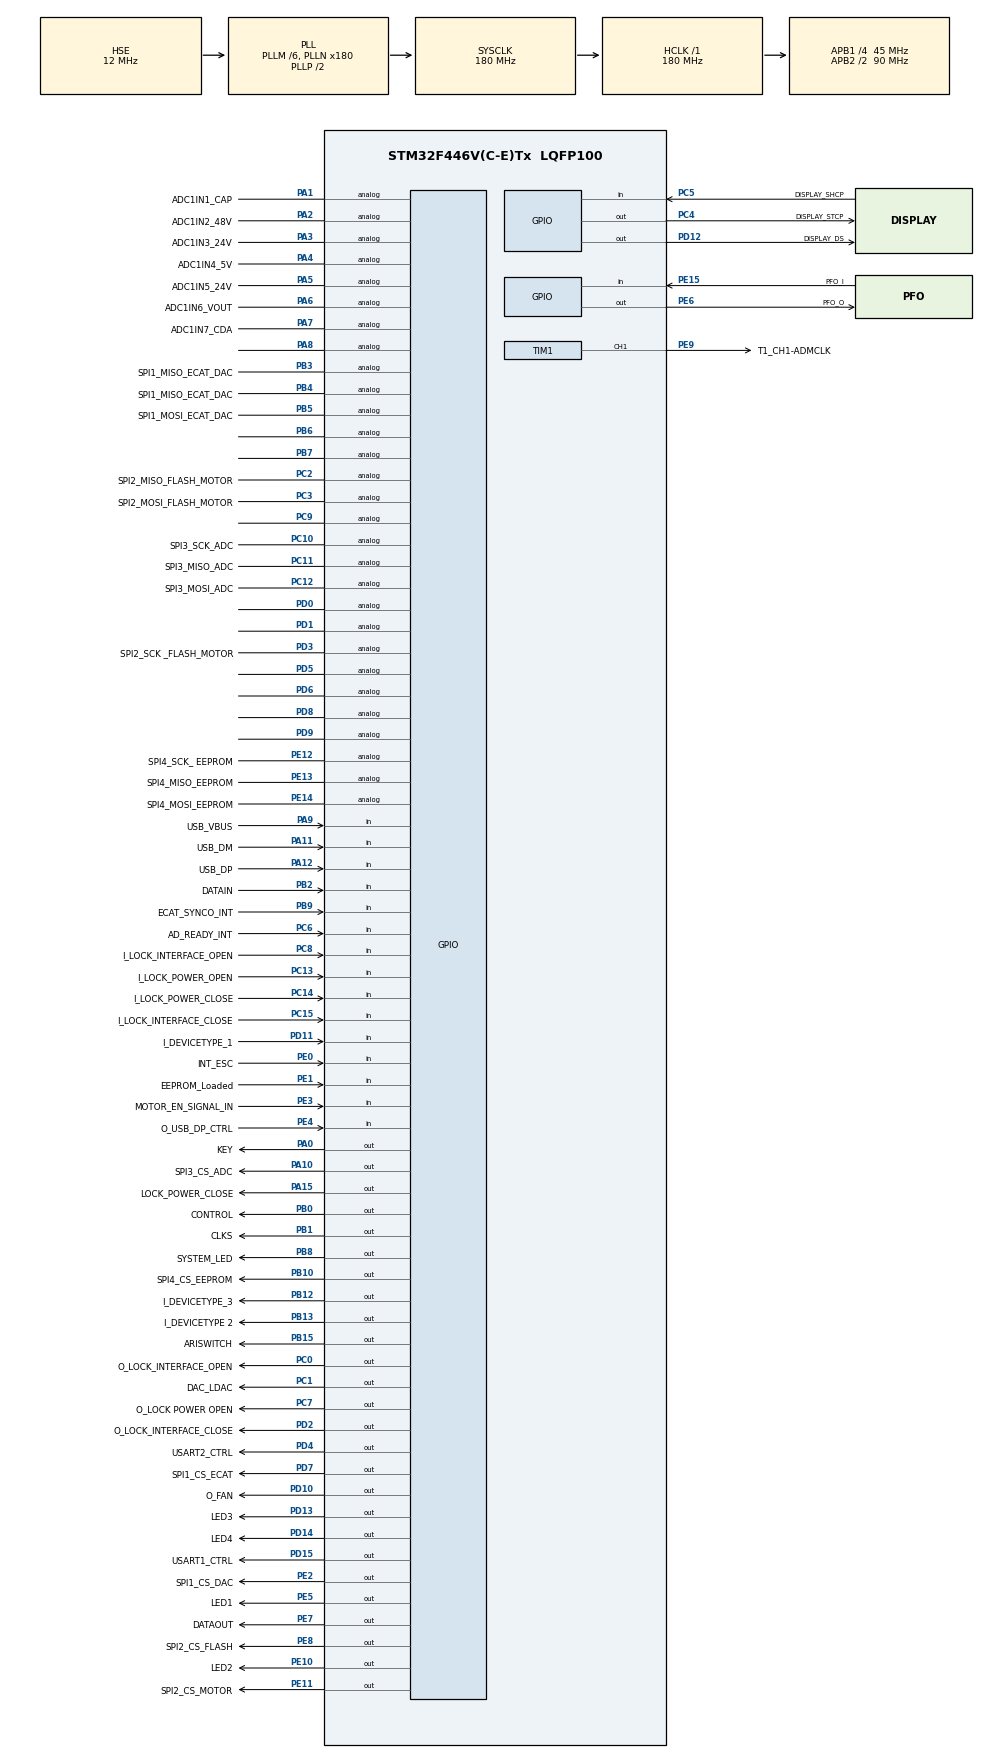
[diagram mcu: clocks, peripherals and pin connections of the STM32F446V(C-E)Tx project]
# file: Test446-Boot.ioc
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board=custom
Dma.ADC1.0.Direction=DMA_PERIPH_TO_MEMORY
Dma.ADC1.0.FIFOMode=DMA_FIFOMODE_DISABLE
Dma.ADC1.0.Instance=DMA2_Stream0
Dma.ADC1.0.MemDataAlignment=DMA_MDATAALIGN_WORD
Dma.ADC1.0.MemInc=DMA_MINC_ENABLE
Dma.ADC1.0.Mode=DMA_CIRCULAR
Dma.ADC1.0.PeriphDataAlignment=DMA_PDATAALIGN_WORD
Dma.ADC1.0.PeriphInc=DMA_PINC_DISABLE
Dma.ADC1.0.Priority=DMA_PRIORITY_LOW
Dma.I2C3_RX.1.Direction=DMA_PERIPH_TO_MEMORY
Dma.I2C3_RX.1.FIFOMode=DMA_FIFOMODE_DISABLE
Dma.I2C3_RX.1.Instance=DMA1_Stream1
Dma.I2C3_RX.1.MemDataAlignment=DMA_MDATAALIGN_BYTE
Dma.I2C3_RX.1.MemInc=DMA_MINC_ENABLE
Dma.I2C3_RX.1.Mode=DMA_NORMAL
Dma.I2C3_RX.1.PeriphDataAlignment=DMA_PDATAALIGN_BYTE
Dma.I2C3_RX.1.PeriphInc=DMA_PINC_DISABLE
Dma.I2C3_RX.1.Priority=DMA_PRIORITY_LOW
Dma.I2C3_TX.2.Direction=DMA_MEMORY_TO_PERIPH
Dma.I2C3_TX.2.FIFOMode=DMA_FIFOMODE_DISABLE
Dma.I2C3_TX.2.Instance=DMA1_Stream4
Dma.I2C3_TX.2.MemDataAlignment=DMA_MDATAALIGN_BYTE
Dma.I2C3_TX.2.MemInc=DMA_MINC_ENABLE
Dma.I2C3_TX.2.Mode=DMA_NORMAL
Dma.I2C3_TX.2.PeriphDataAlignment=DMA_PDATAALIGN_BYTE
Dma.I2C3_TX.2.PeriphInc=DMA_PINC_DISABLE
Dma.I2C3_TX.2.Priority=DMA_PRIORITY_LOW
Dma.Request0=ADC1
Dma.Request1=I2C3_RX
Dma.Request2=I2C3_TX
IWDG.Prescaler=IWDG_PRESCALER_32
Mcu.Family=STM32F4
Mcu.Name=STM32F446V(C-E)Tx
Mcu.Package=LQFP100
NVIC.OTG_FS_IRQn=true\:5\:0\:false\:false\:true\:true\:true\:true\:true
NVIC.PriorityGroup=NVIC_PRIORITYGROUP_4
NVIC.TIM7_IRQn=true\:15\:0\:false\:false\:true\:false\:false\:true\:true
NVIC.TimeBase=TIM7_IRQn
NVIC.TimeBaseIP=TIM7
PA0-WKUP.GPIO_Label=KEY
PA0-WKUP.Signal=GPIO_Output
PA1.GPIO_Label=ADC1IN1_CAP
PA1.Signal=GPIO_Analog
PA10.GPIO_Label=SPI3_CS_ADC
PA10.Signal=GPIO_Output
PA11.GPIO_Label=USB_DM
PA11.GPIO_PuPd=GPIO_NOPULL
PA11.Signal=GPIO_Input
PA12.GPIO_Label=USB_DP
PA12.GPIO_PuPd=GPIO_NOPULL
PA12.Signal=GPIO_Input
PA13.Mode=Serial_Wire
PA13.Signal=SYS_JTMS-SWDIO
PA14.Mode=Serial_Wire
PA14.Signal=SYS_JTCK-SWCLK
PA15.GPIO_Label=LOCK_POWER_CLOSE
PA15.Signal=GPIO_Output
PA2.GPIO_Label=ADC1IN2_48V
PA2.Signal=GPIO_Analog
PA3.GPIO_Label=ADC1IN3_24V
PA3.Signal=GPIO_Analog
PA4.GPIO_Label=ADC1IN4_5V
PA4.Signal=GPIO_Analog
PA5.GPIO_Label=ADC1IN5_24V
PA5.Signal=GPIO_Analog
PA6.GPIO_Label=ADC1IN6_VOUT
PA6.Signal=GPIO_Analog
PA7.GPIO_Label=ADC1IN7_CDA
PA7.Signal=GPIO_Analog
PA8.GPIO_Pu=GPIO_PULLUP
PA8.Signal=GPIO_Analog
PA9.GPIO_Label=USB_VBUS
PA9.GPIO_PuPd=GPIO_NOPULL
PA9.Signal=GPIO_Input
PB0.GPIO_Label=CONTROL
PB0.Signal=GPIO_Output
PB1.GPIO_Label=CLKS
PB1.Signal=GPIO_Output
PB10.GPIO_Label=SPI4_CS_EEPROM
PB10.Signal=GPIO_Output
PB12.GPIO_Label=I_DEVICETYPE_3
PB12.Signal=GPIO_Output
PB13.GPIO_Label=I_DEVICETYPE 2
PB13.Signal=GPIO_Output
PB15.GPIO_Label=ARISWITCH
PB15.Signal=GPIO_Output
PB2.GPIO_Label=DATAIN
PB2.Signal=GPIO_Input
PB3.GPIO_Label=SPI1_MISO_ECAT_DAC
PB3.GPIO_PuPd=GPIO_PULLUP
PB3.Signal=GPIO_Analog
PB4.GPIO_Label=SPI1_MISO_ECAT_DAC
PB4.GPIO_PuPd=GPIO_PULLUP
PB4.Signal=GPIO_Analog
PB5.GPIO_Label=SPI1_MOSI_ECAT_DAC
PB5.GPIO_PuPd=GPIO_PULLUP
PB5.Signal=GPIO_Analog
PB6.Signal=GPIO_Analog
PB7.Signal=GPIO_Analog
PB8.GPIO_Label=SYSTEM_LED
PB8.Signal=GPIO_Output
PB9.GPIO_Label=ECAT_SYNCO_INT
PB9.Signal=GPIO_Input
PC0.GPIO_Label=O_LOCK_INTERFACE_OPEN
PC0.Signal=GPIO_Output
PC1.GPIO_Label=DAC_LDAC
PC1.Signal=GPIO_Output
PC10.GPIO_Label=SPI3_SCK_ADC
PC10.GPIO_PuPd=GPIO_PULLUP
PC10.Signal=GPIO_Analog
PC11.GPIO_Label=SPI3_MISO_ADC
PC11.GPIO_PuPd=GPIO_PULLUP
PC11.Signal=GPIO_Analog
PC12.GPIO_Label=SPI3_MOSI_ADC
PC12.GPIO_PuPd=GPIO_PULLUP
PC12.Signal=GPIO_Analog
PC13.GPIO_Label=I_LOCK_POWER_OPEN
PC13.Signal=GPIO_Input
PC14-OSC32_IN.GPIO_Label=I_LOCK_POWER_CLOSE
PC14-OSC32_IN.Signal=GPIO_Input
PC15-OSC32_OUT.GPIO_Label=I_LOCK_INTERFACE_CLOSE
PC15-OSC32_OUT.Signal=GPIO_Input
PC2.GPIO_Label=SPI2_MISO_FLASH_MOTOR
PC2.GPIO_PuPd=GPIO_PULLUP
PC2.Signal=GPIO_Analog
PC3.GPIO_Label=SPI2_MOSI_FLASH_MOTOR
PC3.GPIO_PuPd=GPIO_PULLUP
PC3.Signal=GPIO_Analog
PC4.GPIO_Label=DISPLAY_STCP
PC4.Signal=GPIO_Output
PC5.GPIO_Label=DISPLAY_SHCP
PC5.Signal=GPIO_Input
PC6.GPIO_Label=AD_READY_INT
PC6.Signal=GPIO_Input
PC7.GPIO_Label=O_LOCK POWER OPEN
PC7.Signal=GPIO_Output
PC8.GPIO_Label=I_LOCK_INTERFACE_OPEN
PC8.Signal=GPIO_Input
PC9.GPIO_Pu=GPIO_PULLUP
PC9.Signal=GPIO_Analog
PD0.GPIO_PuPd=GPIO_NOPULL
PD0.Signal=GPIO_Analog
PD1.GPIO_PuPd=GPIO_NOPULL
PD1.Signal=GPIO_Analog
PD10.GPIO_Label=O_FAN
PD10.Signal=GPIO_Output
PD11.GPIO_Label=I_DEVICETYPE_1
PD11.Signal=GPIO_Input
PD12.GPIO_Label=DISPLAY_DS
PD12.Signal=GPIO_Output
PD13.GPIO_Label=LED3
PD13.Signal=GPIO_Output
PD14.GPIO_Label=LED4
PD14.Signal=GPIO_Output
PD15.GPIO_Label=USART1_CTRL
PD15.Signal=GPIO_Output
PD2.GPIO_Label=O_LOCK_INTERFACE_CLOSE
PD2.GPIO_PuPd=GPIO_PULLUP
PD2.Signal=GPIO_Output
PD3.GPIO_Label=SPI2_SCK _FLASH_MOTOR
PD3.GPIO_PuPd=GPIO_PULLUP
PD3.Signal=GPIO_Analog
PD4.GPIO_Label=USART2_CTRL
PD4.Signal=GPIO_Output
PD5.Signal=GPIO_Analog
PD6.Signal=GPIO_Analog
PD7.GPIO_Label=SPI1_CS_ECAT
PD7.Signal=GPIO_Output
PD8.Signal=GPIO_Analog
PD9.Signal=GPIO_Analog
PE0.GPIO_Label=INT_ESC
PE0.Signal=GPIO_Input
PE1.GPIO_Label=EEPROM_Loaded
PE1.Signal=GPIO_Input
PE10.GPIO_Label=LED2
PE10.Signal=GPIO_Output
PE11.GPIO_Label=SPI2_CS_MOTOR
PE11.PinState=GPIO_PIN_SET
PE11.Signal=GPIO_Output
PE12.GPIO_Label=SPI4_SCK_ EEPROM
PE12.GPIO_PuPd=GPIO_PULLUP
PE12.Signal=GPIO_Analog
PE13.GPIO_Label=SPI4_MISO_EEPROM
PE13.GPIO_PuPd=GPIO_PULLUP
PE13.Signal=GPIO_Analog
PE14.GPIO_Label=SPI4_MOSI_EEPROM
PE14.GPIO_PuPd=GPIO_PULLUP
PE14.Signal=GPIO_Analog
PE15.GPIO_Label=PFO_I
PE15.Signal=GPIO_Input
PE2.GPIO_Label=SPI1_CS_DAC
PE2.Signal=GPIO_Output
PE3.GPIO_Label=MOTOR_EN_SIGNAL_IN
PE3.Signal=GPIO_Input
PE4.GPIO_Label=O_USB_DP_CTRL
PE4.GPIO_PuPd=GPIO_NOPULL
PE4.Signal=GPIO_Input
PE5.GPIO_Label=LED1
PE5.Signal=GPIO_Output
PE6.GPIO_Label=PFO_O
PE6.Signal=GPIO_Output
PE7.GPIO_Label=DATAOUT
PE7.Signal=GPIO_Output
PE8.GPIO_Label=SPI2_CS_FLASH
PE8.PinState=GPIO_PIN_SET
PE8.Signal=GPIO_Output
PE9.GPIO_Label=T1_CH1-ADMCLK
PE9.GPIO_PuPd=GPIO_PULLUP
PE9.GPIO_Speed=GPIO_SPEED_FREQ_VERY_HIGH
PE9.Signal=S_TIM1_CH1
PH0-OSC_IN.Mode=HSE-External-Clock-Source
PH0-OSC_IN.Signal=RCC_OSC_IN
PH1-OSC_OUT.Mode=HSE-External-Clock-Source
PH1-OSC_OUT.Signal=RCC_OSC_OUT
ProjectManager.HeapSize=0x200
ProjectManager.StackSize=0x500
ProjectManager.TargetToolchain=STM32CubeIDE
RCC.AHBFreq_Value=180000000
RCC.APB1CLKDivider=RCC_HCLK_DIV4
RCC.APB1Freq_Value=45000000
RCC.APB1TimFreq_Value=90000000
RCC.APB2CLKDivider=RCC_HCLK_DIV2
RCC.APB2Freq_Value=90000000
RCC.APB2TimFreq_Value=180000000
RCC.CortexFreq_Value=180000000
RCC.HCLKFreq_Value=180000000
RCC.HSE_VALUE=12000000
RCC.PLLM=6
RCC.PLLN=180
RCC.PLLQ=3
RCC.PLLSAIM=6
RCC.PLLSAIN=96
RCC.PLLSAIP=RCC_PLLSAIP_DIV4
RCC.PWR_Regulator_Voltage_Scale=PWR_REGULATOR_VOLTAGE_SCALE1
RCC.PWREXT_OverDrive=PWREXT_OverDrive_ACTIVATED
RCC.SYSCLKFreq_VALUE=180000000
RCC.SYSCLKSource=RCC_SYSCLKSOURCE_PLLCLK
RCC.USBCLockSelection=RCC_CLK48CLKSOURCE_PLLSAIP
RCC.USBFreq_Value=48000000
RCC.VCOOutputFreq_Value=360000000
SH.ADCx_IN1.0=ADC1_IN1,IN1
SH.ADCx_IN2.0=ADC1_IN2,IN2
SH.ADCx_IN3.0=ADC1_IN3,IN3
SH.ADCx_IN4.0=ADC1_IN4,IN4
SH.ADCx_IN5.0=ADC1_IN5,IN5
SH.ADCx_IN6.0=ADC1_IN6,IN6
SH.ADCx_IN7.0=ADC1_IN7,IN7
SH.S_TIM1_CH1.0=TIM1_CH1,PWM Generation1 CH1
VP_IWDG_VS_IWDG.Mode=IWDG_Activate
VP_SYS_VS_tim7.Mode=TIM7
VP_TIM1_VS_ClockSourceINT.Mode=Internal
VP_TIM10_VS_ClockSourceINT.Mode=Enable_Timer
VP_TIM11_VS_ClockSourceINT.Mode=Enable_Timer
VP_TIM12_VS_ClockSourceINT.Mode=Internal
VP_TIM3_VS_ClockSourceINT.Mode=Internal
VP_TIM9_VS_ClockSourceINT.Mode=Internal
RCC.PLLSourceVirtual=RCC_PLLSOURCE_HSE

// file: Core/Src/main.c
/* 独立裸机 Boot；GPIO 安全初态和时钟沿用目标 12MHz 工程。 */
#include "main.h"
/* USER CODE BEGIN Includes */
#include "board.h"
#include "usb_io.h"
#include "usb_proto.h"
#include "fw_platform.h"
/* USER CODE END Includes */
IWDG_HandleTypeDef hiwdg;
void SystemClock_Config(void);
static void MX_GPIO_Init(void);
static void MX_IWDG_Init(void);
int main(void)
{
  HAL_Init(); SystemClock_Config(); MX_GPIO_Init(); MX_IWDG_Init();
  /* USER CODE BEGIN 2 */
  usb_io_init(); fw_platform_boot_start();
  if (!usb_io_stack_init()) Error_Handler();
  /* USER CODE END 2 */
  while (1) {
    /* USER CODE BEGIN 3 */
    usb_io_task(); usb_proto_task(); fw_platform_task(); board_watchdog_refresh();
  }
  /* USER CODE END 3 */
}
void SystemClock_Config(void)
{
  RCC_OscInitTypeDef RCC_OscInitStruct = {0};
  RCC_ClkInitTypeDef RCC_ClkInitStruct = {0};

  /** Configure the main internal regulator output voltage
  */
  __HAL_RCC_PWR_CLK_ENABLE();
  __HAL_PWR_VOLTAGESCALING_CONFIG(PWR_REGULATOR_VOLTAGE_SCALE1);

  /** Initializes the RCC Oscillators according to the specified parameters
  * in the RCC_OscInitTypeDef structure.
  */
  RCC_OscInitStruct.OscillatorType = RCC_OSCILLATORTYPE_LSI|RCC_OSCILLATORTYPE_HSE;
  RCC_OscInitStruct.HSEState = RCC_HSE_BYPASS;
  RCC_OscInitStruct.LSIState = RCC_LSI_ON;
  RCC_OscInitStruct.PLL.PLLState = RCC_PLL_ON;
  RCC_OscInitStruct.PLL.PLLSource = RCC_PLLSOURCE_HSE;
  RCC_OscInitStruct.PLL.PLLM = 6;
  RCC_OscInitStruct.PLL.PLLN = 180;
  RCC_OscInitStruct.PLL.PLLP = RCC_PLLP_DIV2;
  RCC_OscInitStruct.PLL.PLLQ = 3;
  RCC_OscInitStruct.PLL.PLLR = 2;
  if (HAL_RCC_OscConfig(&RCC_OscInitStruct) != HAL_OK)
  {
    Error_Handler();
  }

  /** Activate the Over-Drive mode
  */
  if (HAL_PWREx_EnableOverDrive() != HAL_OK)
  {
    Error_Handler();
  }

  /** Initializes the CPU, AHB and APB buses clocks
  */
  RCC_ClkInitStruct.ClockType = RCC_CLOCKTYPE_HCLK|RCC_CLOCKTYPE_SYSCLK
                              |RCC_CLOCKTYPE_PCLK1|RCC_CLOCKTYPE_PCLK2;
  RCC_ClkInitStruct.SYSCLKSource = RCC_SYSCLKSOURCE_PLLCLK;
  RCC_ClkInitStruct.AHBCLKDivider = RCC_SYSCLK_DIV1;
  RCC_ClkInitStruct.APB1CLKDivider = RCC_HCLK_DIV4;
  RCC_ClkInitStruct.APB2CLKDivider = RCC_HCLK_DIV2;

  if (HAL_RCC_ClockConfig(&RCC_ClkInitStruct, FLASH_LATENCY_5) != HAL_OK)
  {
    Error_Handler();
  }
}
static void MX_GPIO_Init(void)
{
  GPIO_InitTypeDef GPIO_InitStruct = {0};

  /* GPIO Ports Clock Enable */
  __HAL_RCC_GPIOE_CLK_ENABLE();
  __HAL_RCC_GPIOC_CLK_ENABLE();
  __HAL_RCC_GPIOH_CLK_ENABLE();
  __HAL_RCC_GPIOA_CLK_ENABLE();
  __HAL_RCC_GPIOB_CLK_ENABLE();
  __HAL_RCC_GPIOD_CLK_ENABLE();
  HAL_GPIO_WritePin(GPIOE, SPI2_CS_FLASH_Pin | SPI2_CS_MOTOR_Pin, GPIO_PIN_SET);

  /*Configure GPIO pin Output Level */
  HAL_GPIO_WritePin(GPIOE, SPI1_CS_DAC_Pin|LED1_Pin|PFO_O_Pin
                          |DATAOUT_Pin|LED2_Pin, GPIO_PIN_RESET);

  /*Configure GPIO pin Output Level */
  HAL_GPIO_WritePin(GPIOC, O_LOCK_INTERFACE_OPEN_Pin|DAC_LDAC_Pin|DISPLAY_STCP_Pin|O_LOCK_POWER_OPEN_Pin, GPIO_PIN_RESET);

  /*Configure GPIO pin Output Level */
  HAL_GPIO_WritePin(GPIOA, KEY_Pin|SPI3_CS_ADC_Pin|LOCK_POWER_CLOSE_Pin, GPIO_PIN_RESET);

  /*Configure GPIO pin Output Level */
  HAL_GPIO_WritePin(GPIOB, CONTROL_Pin|CLKS_Pin|SPI4_CS_EEPROM_Pin|I_DEVICETYPE_3_Pin
                          |I_DEVICETYPE_2_Pin|ARISWITCH_Pin|SYSTEM_LED_Pin, GPIO_PIN_RESET);

  /*Configure GPIO pin Output Level */
  HAL_GPIO_WritePin(GPIOD, O_FAN_Pin|DISPLAY_DS_Pin|LED3_Pin|LED4_Pin
                          |USART1_CTRL_Pin|O_LOCK_INTERFACE_CLOSE_Pin|USART2_CTRL_Pin|SPI1_CS_ECAT_Pin, GPIO_PIN_RESET);

  /*Configure GPIO pins : SPI1_CS_DAC_Pin O_USB_DP_CTRL_Pin LED1_Pin PFO_O_Pin
                           DATAOUT_Pin SPI2_CS_FLASH_Pin LED2_Pin SPI2_CS_MOTOR_Pin */
  GPIO_InitStruct.Pin = SPI1_CS_DAC_Pin|LED1_Pin|PFO_O_Pin
                          |DATAOUT_Pin|LED2_Pin;
  GPIO_InitStruct.Mode = GPIO_MODE_OUTPUT_PP;
  GPIO_InitStruct.Pull = GPIO_NOPULL;
  GPIO_InitStruct.Speed = GPIO_SPEED_FREQ_LOW;
  HAL_GPIO_Init(GPIOE, &GPIO_InitStruct);

  GPIO_InitStruct.Pin = O_USB_DP_CTRL_Pin;
  GPIO_InitStruct.Mode = GPIO_MODE_INPUT;
  GPIO_InitStruct.Pull = GPIO_NOPULL;
  HAL_GPIO_Init(GPIOE, &GPIO_InitStruct);
  GPIO_InitStruct.Pin = SPI2_CS_FLASH_Pin | SPI2_CS_MOTOR_Pin;
  GPIO_InitStruct.Mode = GPIO_MODE_OUTPUT_PP;
  HAL_GPIO_Init(GPIOE, &GPIO_InitStruct);

  /*Configure GPIO pins : MOTOR_EN_SIGNAL_IN_Pin PFO_I_Pin EEPROM_Loaded_Pin */
  GPIO_InitStruct.Pin = MOTOR_EN_SIGNAL_IN_Pin|PFO_I_Pin|EEPROM_Loaded_Pin;
  GPIO_InitStruct.Mode = GPIO_MODE_INPUT;
  GPIO_InitStruct.Pull = GPIO_NOPULL;
  HAL_GPIO_Init(GPIOE, &GPIO_InitStruct);

  /*Configure GPIO pins : I_LOCK_POWER_OPEN_Pin I_LOCK_POWER_CLOSE_Pin I_LOCK_INTERFACE_CLOSE_Pin I_LOCK_INTERFACE_OPEN_Pin */
  GPIO_InitStruct.Pin = I_LOCK_POWER_OPEN_Pin|I_LOCK_POWER_CLOSE_Pin|I_LOCK_INTERFACE_CLOSE_Pin|I_LOCK_INTERFACE_OPEN_Pin;
  GPIO_InitStruct.Mode = GPIO_MODE_INPUT;
  GPIO_InitStruct.Pull = GPIO_NOPULL;
  HAL_GPIO_Init(GPIOC, &GPIO_InitStruct);

  /*Configure GPIO pins : O_LOCK_INTERFACE_OPEN_Pin DAC_LDAC_Pin DISPLAY_STCP_Pin O_LOCK_POWER_OPEN_Pin */
  GPIO_InitStruct.Pin = O_LOCK_INTERFACE_OPEN_Pin|DAC_LDAC_Pin|DISPLAY_STCP_Pin|O_LOCK_POWER_OPEN_Pin;
  GPIO_InitStruct.Mode = GPIO_MODE_OUTPUT_PP;
  GPIO_InitStruct.Pull = GPIO_NOPULL;
  GPIO_InitStruct.Speed = GPIO_SPEED_FREQ_LOW;
  HAL_GPIO_Init(GPIOC, &GPIO_InitStruct);

  /*Configure GPIO pins : KEY_Pin SPI3_CS_ADC_Pin LOCK_POWER_CLOSE_Pin */
  GPIO_InitStruct.Pin = KEY_Pin|SPI3_CS_ADC_Pin|LOCK_POWER_CLOSE_Pin;
  GPIO_InitStruct.Mode = GPIO_MODE_OUTPUT_PP;
  GPIO_InitStruct.Pull = GPIO_NOPULL;
  GPIO_InitStruct.Speed = GPIO_SPEED_FREQ_LOW;
  HAL_GPIO_Init(GPIOA, &GPIO_InitStruct);

  /*Configure GPIO pins : DISPLAY_SHCP_Pin AD_READY_INT_Pin */
  GPIO_InitStruct.Pin = DISPLAY_SHCP_Pin|AD_READY_INT_Pin;
  GPIO_InitStruct.Mode = GPIO_MODE_INPUT;
  GPIO_InitStruct.Pull = GPIO_NOPULL;
  HAL_GPIO_Init(GPIOC, &GPIO_InitStruct);

  /*Configure GPIO pins : CONTROL_Pin CLKS_Pin SPI4_CS_EEPROM_Pin I_DEVICETYPE_3_Pin
                           I_DEVICETYPE_2_Pin ARISWITCH_Pin SYSTEM_LED_Pin */
  GPIO_InitStruct.Pin = CONTROL_Pin|CLKS_Pin|SPI4_CS_EEPROM_Pin|I_DEVICETYPE_3_Pin
                          |I_DEVICETYPE_2_Pin|ARISWITCH_Pin|SYSTEM_LED_Pin;
  GPIO_InitStruct.Mode = GPIO_MODE_OUTPUT_PP;
  GPIO_InitStruct.Pull = GPIO_NOPULL;
  GPIO_InitStruct.Speed = GPIO_SPEED_FREQ_LOW;
  HAL_GPIO_Init(GPIOB, &GPIO_InitStruct);

  /*Configure GPIO pin : DATAIN_Pin */
  GPIO_InitStruct.Pin = DATAIN_Pin;
  GPIO_InitStruct.Mode = GPIO_MODE_INPUT;
  GPIO_InitStruct.Pull = GPIO_NOPULL;
  HAL_GPIO_Init(DATAIN_GPIO_Port, &GPIO_InitStruct);

  /*Configure GPIO pins : O_FAN_Pin DISPLAY_DS_Pin LED3_Pin LED4_Pin
                           USART1_CTRL_Pin USART2_CTRL_Pin SPI1_CS_ECAT_Pin */
  GPIO_InitStruct.Pin = O_FAN_Pin|DISPLAY_DS_Pin|LED3_Pin|LED4_Pin
                          |USART1_CTRL_Pin|USART2_CTRL_Pin|SPI1_CS_ECAT_Pin;
  GPIO_InitStruct.Mode = GPIO_MODE_OUTPUT_PP;
  GPIO_InitStruct.Pull = GPIO_NOPULL;
  GPIO_InitStruct.Speed = GPIO_SPEED_FREQ_LOW;
  HAL_GPIO_Init(GPIOD, &GPIO_InitStruct);

  /*Configure GPIO pin : I_DEVICETYPE_1_Pin */
  GPIO_InitStruct.Pin = I_DEVICETYPE_1_Pin;
  GPIO_InitStruct.Mode = GPIO_MODE_INPUT;
  GPIO_InitStruct.Pull = GPIO_NOPULL;
  HAL_GPIO_Init(I_DEVICETYPE_1_GPIO_Port, &GPIO_InitStruct);

  /*Configure GPIO pin : O_LOCK_INTERFACE_CLOSE_Pin */
  GPIO_InitStruct.Pin = O_LOCK_INTERFACE_CLOSE_Pin;
  GPIO_InitStruct.Mode = GPIO_MODE_OUTPUT_PP;
  GPIO_InitStruct.Pull = GPIO_PULLUP;
  GPIO_InitStruct.Speed = GPIO_SPEED_FREQ_LOW;
  HAL_GPIO_Init(O_LOCK_INTERFACE_CLOSE_GPIO_Port, &GPIO_InitStruct);

  /*Configure GPIO pin : ECAT_SYNCO_INT_Pin */
  GPIO_InitStruct.Pin = ECAT_SYNCO_INT_Pin;
  GPIO_InitStruct.Mode = GPIO_MODE_INPUT;
  GPIO_InitStruct.Pull = GPIO_NOPULL;
  HAL_GPIO_Init(ECAT_SYNCO_INT_GPIO_Port, &GPIO_InitStruct);

  /*Configure GPIO pin : INT_ESC_Pin */
  GPIO_InitStruct.Pin = INT_ESC_Pin;
  GPIO_InitStruct.Mode = GPIO_MODE_INPUT;
  GPIO_InitStruct.Pull = GPIO_NOPULL;
  HAL_GPIO_Init(INT_ESC_GPIO_Port, &GPIO_InitStruct);

}
static void MX_IWDG_Init(void)
{

  hiwdg.Instance = IWDG;
  hiwdg.Init.Prescaler = IWDG_PRESCALER_32;
  hiwdg.Init.Reload = 4095;
  if (HAL_IWDG_Init(&hiwdg) != HAL_OK)
  {
    Error_Handler();
  }

}
/* USER CODE BEGIN 4 */
void HAL_TIM_PeriodElapsedCallback(TIM_HandleTypeDef *timer)
{
  if (timer->Instance == TIM7) HAL_IncTick();
}
/* USER CODE END 4 */
void Error_Handler(void) { __disable_irq(); for (;;) {} }
